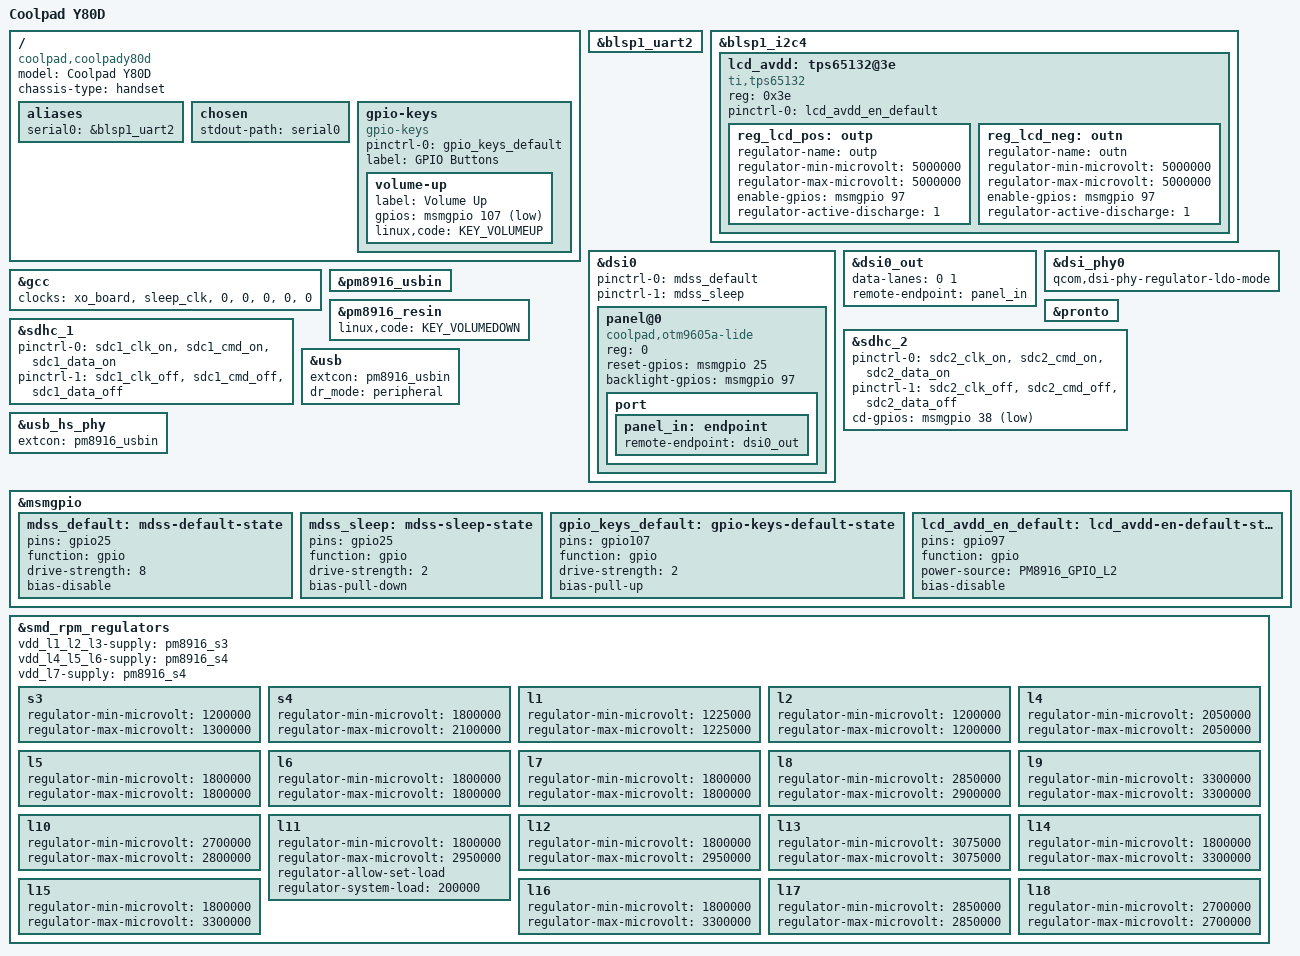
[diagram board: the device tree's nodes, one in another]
// SPDX-License-Identifier: GPL-2.0-only

/dts-v1/;

#include "msm8916-pm8916.dtsi"
#include <dt-bindings/gpio/gpio.h>
#include <dt-bindings/input/input.h>

/ {
	model = "Coolpad Y80D";
	compatible = "coolpad,coolpady80d", "qcom,msm8916";
	chassis-type = "handset";
	
	aliases {
		serial0 = &blsp1_uart2;
	};
	
	chosen {
		stdout-path = "serial0";
	};

	gpio-keys {
		compatible = "gpio-keys";

		pinctrl-names = "default";
		pinctrl-0 = <&gpio_keys_default>;

		label = "GPIO Buttons";

		volume-up {
			label = "Volume Up";
			gpios = <&msmgpio 107 GPIO_ACTIVE_LOW>;
			linux,code = <KEY_VOLUMEUP>;
		};
	};
	
};

&blsp1_uart2 {
	status = "okay";
	// THIS SHIT HAS UART ON THE USB ID PIN
};

&blsp1_i2c4 {
	status = "okay";
	
	lcd_avdd: tps65132@3e {
		compatible = "ti,tps65132";
		reg = <0x3e>;

		pinctrl-0 = <&lcd_avdd_en_default>;
		pinctrl-names = "default";

		reg_lcd_pos: outp {
			regulator-name = "outp";
			regulator-min-microvolt = <5000000>;
			regulator-max-microvolt = <5000000>;
			enable-gpios = <&msmgpio 97 GPIO_ACTIVE_HIGH>;
			regulator-active-discharge = <1>;
		};

		reg_lcd_neg: outn {
			regulator-name = "outn";
			regulator-min-microvolt = <5000000>;
			regulator-max-microvolt = <5000000>;
			enable-gpios = <&msmgpio 97 GPIO_ACTIVE_HIGH>;
			regulator-active-discharge = <1>;
		};
	};
};
//generated by lmdpdg
&dsi0 {
	pinctrl-0 = <&mdss_default>;
	pinctrl-1 = <&mdss_sleep>;
	pinctrl-names = "default", "sleep";

        panel@0 {
                compatible = "coolpad,otm9605a-lide", "coolpad,otm9605a-boyi", "coolpad,otm9605a-yashi", "coolpad,otm9605a-dijing", "coolpad,otm9605a-boyiotp", "coolpad,himax8389c-yashi", "coolpad,himax8389c-yashiotp", "otm9605a-oufei";
                reg = <0>;

                reset-gpios = <&msmgpio 25 GPIO_ACTIVE_HIGH>;
                backlight-gpios = <&msmgpio 97 GPIO_ACTIVE_HIGH>;
                
                port {
                        panel_in: endpoint {
                                remote-endpoint = <&dsi0_out>;
                        };
                };
        };
};

&dsi0_out {
        data-lanes = <0 1>;
        remote-endpoint = <&panel_in>;
};

&dsi_phy0 {
        qcom,dsi-phy-regulator-ldo-mode;
};

&gcc {
	clocks = <&xo_board>, <&sleep_clk>, <0>, <0>, <0>, <0>, <0>;
};
//USB-ID pin "present", but occupied by UART.
//This PM8916 inplementation is used as a workaround
&pm8916_usbin {
	status = "okay";
};

&pm8916_resin {
	linux,code = <KEY_VOLUMEDOWN>;
	status = "okay";
};

&pronto {
	status = "okay";
	//this device uses WCN3620
};

&sdhc_1 {
	pinctrl-names = "default", "sleep";
	pinctrl-0 = <&sdc1_clk_on &sdc1_cmd_on &sdc1_data_on>;
	pinctrl-1 = <&sdc1_clk_off &sdc1_cmd_off &sdc1_data_off>;

	status = "okay";
};

&sdhc_2 {
	pinctrl-names = "default", "sleep";
	pinctrl-0 = <&sdc2_clk_on &sdc2_cmd_on &sdc2_data_on>;  // add &sdc2_cd_on if you use cd-gpios below
	pinctrl-1 = <&sdc2_clk_off &sdc2_cmd_off &sdc2_data_off>; // add &sdc2_cd_off if you use cd-gpios below

	cd-gpios = <&msmgpio 38 GPIO_ACTIVE_LOW>;

	status = "okay";
};

&usb {
	extcon = <&pm8916_usbin>;
	dr_mode = "peripheral";
	status = "okay";
};

&usb_hs_phy {
	extcon = <&pm8916_usbin>;
};

&msmgpio {
	mdss_default: mdss-default-state {
		pins = "gpio25";
		function = "gpio";

		drive-strength = <8>;
		bias-disable;
	};

	mdss_sleep: mdss-sleep-state {
		pins = "gpio25";
		function = "gpio";

		drive-strength = <2>;
		bias-pull-down;
	};
	
	gpio_keys_default: gpio-keys-default-state {
		pins = "gpio107";
		function = "gpio";
		drive-strength = <2>;
		bias-pull-up;
	};
	
	lcd_avdd_en_default: lcd_avdd-en-default-state {
		pins = "gpio97";
		function = "gpio";
		power-source = <PM8916_GPIO_L2>;
		bias-disable;
	};
};

&smd_rpm_regulators {
	vdd_l1_l2_l3-supply = <&pm8916_s3>;
	vdd_l4_l5_l6-supply = <&pm8916_s4>;
	vdd_l7-supply = <&pm8916_s4>;

	s3 {
		regulator-min-microvolt = <1200000>;
		regulator-max-microvolt = <1300000>;
	};

	s4 {
		regulator-min-microvolt = <1800000>;
		regulator-max-microvolt = <2100000>;
	};

	l1 {
		regulator-min-microvolt = <1225000>;
		regulator-max-microvolt = <1225000>;
	};

	l2 {
		regulator-min-microvolt = <1200000>;
		regulator-max-microvolt = <1200000>;
	};

	l4 {
		regulator-min-microvolt = <2050000>;
		regulator-max-microvolt = <2050000>;
	};

	l5 {
		regulator-min-microvolt = <1800000>;
		regulator-max-microvolt = <1800000>;
	};

	l6 {
		regulator-min-microvolt = <1800000>;
		regulator-max-microvolt = <1800000>;
	};

	l7 {
		regulator-min-microvolt = <1800000>;
		regulator-max-microvolt = <1800000>;
	};

	l8 {
		regulator-min-microvolt = <2850000>;
		regulator-max-microvolt = <2900000>;
	};

	l9 {
		regulator-min-microvolt = <3300000>;
		regulator-max-microvolt = <3300000>;
	};

	l10 {
		regulator-min-microvolt = <2700000>;
		regulator-max-microvolt = <2800000>;
	};

	l11 {
		regulator-min-microvolt = <1800000>;
		regulator-max-microvolt = <2950000>;
		regulator-allow-set-load;
		regulator-system-load = <200000>;
	};

	l12 {
		regulator-min-microvolt = <1800000>;
		regulator-max-microvolt = <2950000>;
	};

	l13 {
		regulator-min-microvolt = <3075000>;
		regulator-max-microvolt = <3075000>;
	};

	l14 {
		regulator-min-microvolt = <1800000>;
		regulator-max-microvolt = <3300000>;
	};

	l15 {
		regulator-min-microvolt = <1800000>;
		regulator-max-microvolt = <3300000>;
	};

	l16 {
		regulator-min-microvolt = <1800000>;
		regulator-max-microvolt = <3300000>;
	};

	l17 {
		regulator-min-microvolt = <2850000>;
		regulator-max-microvolt = <2850000>;
	};

	l18 {
		regulator-min-microvolt = <2700000>;
		regulator-max-microvolt = <2700000>;
	};
};
